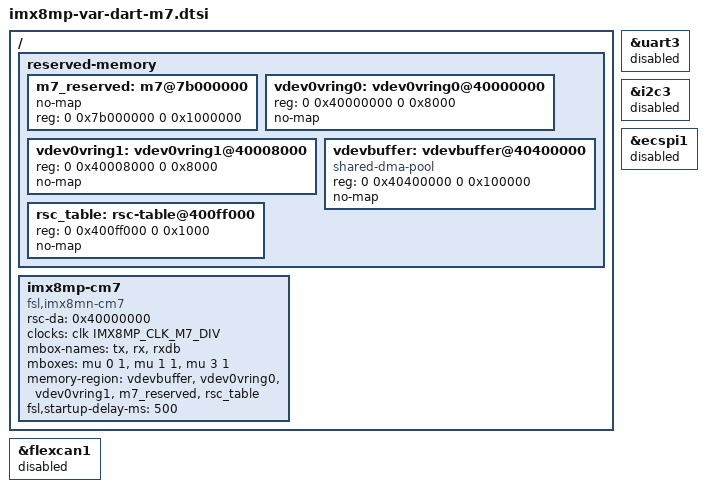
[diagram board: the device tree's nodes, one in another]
// SPDX-License-Identifier: (GPL-2.0+ OR MIT)
/*
 * Copyright (C) 2026 Variscite Ltd. - https://www.variscite.com/
 *
 */

/ {
	reserved-memory {
		#address-cells = <2>;
		#size-cells = <2>;
		ranges;

		m7_reserved: m7@7b000000 {
			no-map;
			reg = <0 0x7b000000 0 0x1000000>;
		};

		vdev0vring0: vdev0vring0@40000000 {
			reg = <0 0x40000000 0 0x8000>;
			no-map;
		};

		vdev0vring1: vdev0vring1@40008000 {
			reg = <0 0x40008000 0 0x8000>;
			no-map;
		};

		vdevbuffer: vdevbuffer@40400000 {
			compatible = "shared-dma-pool";
			reg = <0 0x40400000 0 0x100000>;
			no-map;
		};

		rsc_table: rsc-table@400ff000 {
			reg = <0 0x400ff000 0 0x1000>;
			no-map;
		};
	};

	imx8mp-cm7 {
		compatible = "fsl,imx8mn-cm7";
		rsc-da = <0x40000000>;
		clocks = <&clk IMX8MP_CLK_M7_DIV>;
		mbox-names = "tx", "rx", "rxdb";
		mboxes = <&mu 0 1
			  &mu 1 1
			  &mu 3 1>;
		memory-region = <&vdevbuffer>, <&vdev0vring0>, <&vdev0vring1>,
				<&m7_reserved>, <&rsc_table>;
		fsl,startup-delay-ms = <500>;
		status = "okay";
	};
};

&uart3 {
	status = "disabled";
};

&i2c3 {
	status = "disabled";
};

&ecspi1 {
	status = "disabled";
};

&flexcan1 {
	status = "disabled";
};
